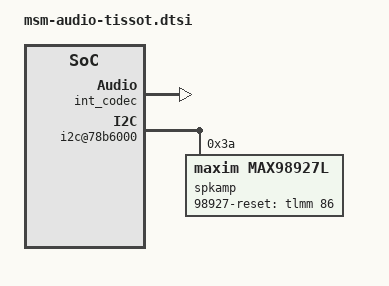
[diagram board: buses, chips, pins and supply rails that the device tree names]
/*
 * Copyright (c) 2015-2017, The Linux Foundation. All rights reserved.
 *
 * This program is free software; you can redistribute it and/or modify
 * it under the terms of the GNU General Public License version 2 and
 * only version 2 as published by the Free Software Foundation.
 *
 * This program is distributed in the hope that it will be useful,
 * but WITHOUT ANY WARRANTY; without even the implied warranty of
 * MERCHANTABILITY or FITNESS FOR A PARTICULAR PURPOSE.  See the
 * GNU General Public License for more details.
 */

&soc {

	int_codec: sound {
		status = "ok";
		qcom,msm-hs-micbias-type = "internal";
		qcom,audio-routing =
			"RX_BIAS", "MCLK",
			"SPK_RX_BIAS", "MCLK",
			"INT_LDO_H", "MCLK",
			"MIC BIAS External", "Handset Mic",
			"MIC BIAS Internal2", "Headset Mic",
			"MIC BIAS External", "Secondary Mic",
			"AMIC1", "MIC BIAS External",
			"AMIC2", "MIC BIAS Internal2",
			"AMIC3", "MIC BIAS External";
		/delete-property/ qcom,hdmi-dba-codec-rx;

	};

	i2c@78b6000 {
		spkamp@3a {/* max98927 smartpa device*/
			compatible = "maxim,max98927L";
			status = "okay";
			reg = <0x3a>;
			mono_stereo_mode = <0>;
			interleave_mode = <0>;
			vmon-l-slot = <1>;
			imon-l-slot = <1>;
			vmon-r-slot = <1>;
			imon-r-slot = <1>;
			maxim,98927-reset-gpio = <&tlmm 86 0>;
		};
	};

        cdc_ext_pa_gpios: cdc_ext_pa_pinctrl {
                compatible = "qcom,msm-cdc-pinctrl";
                pinctrl-names = "aud_active", "aud_sleep";
                pinctrl-0 = <&ext_pa_power_on>;
                pinctrl-1 = <&ext_pa_power_off>;
        };

};

